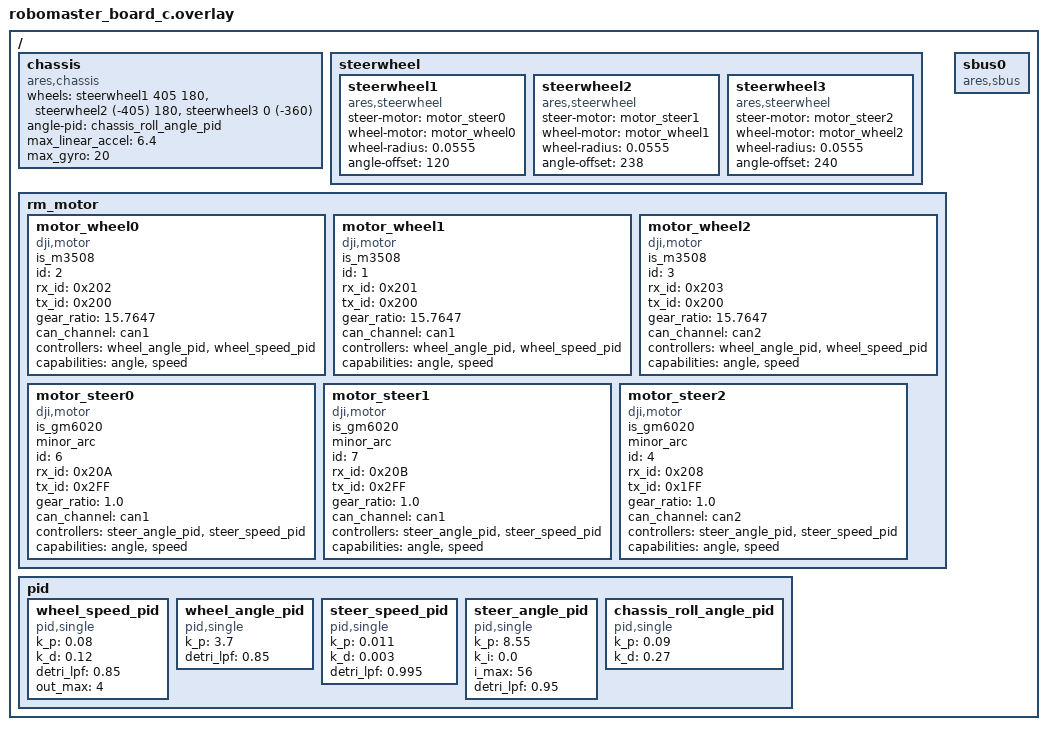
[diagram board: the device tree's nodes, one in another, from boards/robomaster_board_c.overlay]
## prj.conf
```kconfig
# 启用线程分析器
CONFIG_THREAD_ANALYZER=y
CONFIG_THREAD_ANALYZER_USE_LOG=y
CONFIG_THREAD_ANALYZER_USE_PRINTK=n
CONFIG_THREAD_NAME=y
# CONFIG_THREAD_ANALYZER_AUTO=y
# CONFIG_THREAD_ANALYZER_AUTO_INTERVAL=5
CONFIG_THREAD_ANALYZER_LOG_LEVEL_INF=y
CONFIG_THREAD_ANALYZER_AUTO_SEPARATE_CORES=n

# 启用 Shell 支持
CONFIG_SHELL=n
CONFIG_SHELL_BACKENDS=n
CONFIG_SHELL_BACKEND_SERIAL=n

# 启用 UART 控制台
CONFIG_UART_CONSOLE=y

# 禁用 SEGGER RTT
CONFIG_USE_SEGGER_RTT=n

# 启用事件支持
CONFIG_EVENTS=y

# 启用控制台支持
CONFIG_CONSOLE=y

# 启用日志系统
CONFIG_LOG=y
CONFIG_LOG_MODE_IMMEDIATE=y
CONFIG_LOG_PRINTK=y
CONFIG_LOG_BACKEND_UART=y
# CONFIG_LOG_MODE_IMMEDIATE=y

# 启用串行支持
CONFIG_SERIAL=y

# 禁用优化
CONFIG_NO_OPTIMIZATIONS=n

# 启用驱动
CONFIG_MOTOR=y
CONFIG_MOTOR_DJI=y
CONFIG_MOTOR_LOG_LEVEL=4
CONFIG_CAN=y
CONFIG_MOTOR_INIT_PRIORITY=90

CONFIG_ARES=y
CONFIG_ARES_SBUS=y
CONFIG_EKF_LIB=y
CONFIG_VOFA_LIB=y

CONFIG_AUTO_PROBE_GYRO_BIAS=y

# use ASYNC uart API
CONFIG_SERIAL=y
CONFIG_UART_ASYNC_API=y
CONFIG_UART_INTERRUPT_DRIVEN=y

CONFIG_DMA=y
CONFIG_DMA_STM32=y  # STM32 DMA 驱动
CONFIG_UART_STM32=y # STM32 UART 驱动
# CONFIG_STM32_UART_DMA=y

# CONFIG_HAS_STM32CUBE=y
# CONFIG_USE_STM32_HAL_DMA=y
CONFIG_SPI=y
CONFIG_SPI_STM32=y

CONFIG_CMSIS_DSP=y
CONFIG_CMSIS_DSP_MATRIX=y
CONFIG_CMSIS_DSP_CONTROLLER=y
CONFIG_CMSIS_DSP_FASTMATH=y

CONFIG_ZBUS=y
CONFIG_ZBUS_LOG_LEVEL_OFF=y
CONFIG_ZBUS_MSG_SUBSCRIBER=y
CONFIG_ZBUS_RUNTIME_OBSERVERS=y

CONFIG_CHASSIS=y
```

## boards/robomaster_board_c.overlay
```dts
/ {
    chassis: chassis {
        compatible = "ares,chassis";
        status = "okay";
        wheels = <&steerwheel1   405    180>,  /* 右前 */
                 <&steerwheel2 (-405)     180>,  /* 左前 */
                 <&steerwheel3     0  (-360)>;  /* 中后 */
        angle-pid = <&chassis_roll_angle_pid>;
        max_linear_accel = "6.4";
        max_gyro = "20";
    };

    steerwheel {
        steerwheel1: steerwheel1 {
            #wheel-cells = <2>;
            compatible = "ares,steerwheel";
            status = "okay";
            steer-motor = <&motor_steer0>;
            wheel-motor = <&motor_wheel0>;
            wheel-radius = "0.0555";
            angle-offset = "120";
        };

        steerwheel2: steerwheel2 {
            #wheel-cells = <2>;
            compatible = "ares,steerwheel";
            status = "okay";
            steer-motor = <&motor_steer1>;
            wheel-motor = <&motor_wheel1>;
            wheel-radius = "0.0555";
            angle-offset = "238";
        };

        steerwheel3: steerwheel3 {
            #wheel-cells = <2>;
            compatible = "ares,steerwheel";
            status = "okay";
            steer-motor = <&motor_steer2>;
            wheel-motor = <&motor_wheel2>;
            wheel-radius = "0.0555";
            angle-offset = "240";
        };
    };

    rm_motor {
        motor_wheel0: motor_wheel0 {
            compatible = "dji,motor";
            is_m3508;
            id = <2>;
            rx_id = <0x202>;
            tx_id = <0x200>;
            gear_ratio = "15.7647";
            status = "okay";
            can_channel = <&can1>;
            controllers = <&wheel_angle_pid &wheel_speed_pid>;
            capabilities = "angle", "speed";
        };

        motor_wheel1: motor_wheel1 {
            compatible = "dji,motor";
            is_m3508;
            id = <1>;
            rx_id = <0x201>;
            tx_id = <0x200>;
            gear_ratio = "15.7647";
            status = "okay";
            can_channel = <&can1>;
            controllers = <&wheel_angle_pid &wheel_speed_pid>;
            capabilities = "angle", "speed";
        };

        motor_wheel2: motor_wheel2 {
            compatible = "dji,motor";
            is_m3508;
            id = <3>;
            rx_id = <0x203>;
            tx_id = <0x200>;
            gear_ratio = "15.7647";
            status = "okay";
            can_channel = <&can2>;
            controllers = <&wheel_angle_pid &wheel_speed_pid>;
            capabilities = "angle", "speed";
        };

        motor_steer0: motor_steer0 {
            compatible = "dji,motor";
            is_gm6020;
            minor_arc;
            id = <6>;
            rx_id = <0x20A>;
            tx_id = <0x2FF>;
            gear_ratio = "1.0";
            status = "okay";
            can_channel = <&can1>;
            controllers = <&steer_angle_pid &steer_speed_pid>;
            capabilities = "angle", "speed";
        };

        motor_steer1: motor_steer1 {
            compatible = "dji,motor";
            is_gm6020;
            minor_arc;
            id = <7>;
            rx_id = <0x20B>;
            tx_id = <0x2FF>;
            gear_ratio = "1.0";
            status = "okay";
            can_channel = <&can1>;
            controllers = <&steer_angle_pid &steer_speed_pid>;
            capabilities = "angle", "speed";
        };

        motor_steer2: motor_steer2 {
            compatible = "dji,motor";
            is_gm6020;
            minor_arc;
            id = <4>;
            rx_id = <0x208>;
            tx_id = <0x1FF>;
            gear_ratio = "1.0";
            status = "okay";
            can_channel = <&can2>;
            controllers = <&steer_angle_pid &steer_speed_pid>;
            capabilities = "angle", "speed";
        };
    };

    pid {
        wheel_speed_pid: wheel_speed_pid {
            #controller-cells = <0>;
            compatible = "pid,single";
            k_p = "0.08";
            k_d = "0.12";
            detri_lpf = "0.85";
            out_max = "4";
        };

        wheel_angle_pid: wheel_angle_pid {
            #controller-cells = <0>;
            compatible = "pid,single";
            k_p = "3.7";
            detri_lpf = "0.85";
        };

        steer_speed_pid: steer_speed_pid {
            #controller-cells = <0>;
            compatible = "pid,single";
            k_p = "0.011";
            k_d = "0.003";
            detri_lpf = "0.995";
        };

        steer_angle_pid: steer_angle_pid {
            #controller-cells = <0>;
            compatible = "pid,single";
            k_p = "8.55";
            k_i = "0.0";
            i_max = "56";
            detri_lpf = "0.95";
        };

        chassis_roll_angle_pid: chassis_roll_angle_pid {
            #controller-cells = <0>;
            compatible = "pid,single";
            k_p = "0.09";
            k_d = "0.27";
        };
    };

    sbus0: sbus0 {
        compatible = "ares,sbus";
        status = "okay";
    };
};
```

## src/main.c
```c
/*
 * Copyright (c) 2024 ttwards <12411711@mail.sustech.edu.cn>
 *
 * SPDX-License-Identifier: Apache-2.0
 */

#include <math.h>
#include <stddef.h>
#include <stdint.h>
#include <string.h>
#include <zephyr/device.h>
#include <zephyr/logging/log.h>
#include <zephyr/kernel.h>
#include <zephyr/drivers/motor.h>
#include <zephyr/drivers/sbus.h>
#include <zephyr/drivers/chassis.h>
#include <ares/board/init.h>
#include "devices.h"

LOG_MODULE_REGISTER(main, LOG_LEVEL_DBG);

#define STICK_DEADZONE 0.06f
#define GEAR_SWITCH_DOWN_THRESHOLD -0.5f
#define GEAR_SWITCH_RELEASE_THRESHOLD -0.2f
#define HIGH_LINEAR_SPEED_SCALE 1.5f
#define HIGH_GYRO_SPEED_SCALE 15.0f
#define LOW_LINEAR_SPEED_SCALE 0.5f
#define LOW_GYRO_SPEED_SCALE 7.5f
#define BRAKE_LINEAR_DECEL_MPS2 5.0f
#define BRAKE_GYRO_DECEL_RADPS2 50.0f
#define DEFAULT_CONTROL_DT_SEC 0.005f
#define MAX_CONTROL_DT_SEC 0.05f
#define STOP_LINEAR_EPS 0.02f
#define STOP_GYRO_EPS 0.05f

static float control_dt_seconds(int64_t now_ms, int64_t *last_ms)
{
    if (*last_ms == 0) {
        *last_ms = now_ms;
        return DEFAULT_CONTROL_DT_SEC;
    }

    int64_t elapsed_ms = now_ms - *last_ms;
    *last_ms = now_ms;

    if (elapsed_ms <= 0) {
        return DEFAULT_CONTROL_DT_SEC;
    }

    float dt = (float)elapsed_ms / 1000.0f;

    if (dt > MAX_CONTROL_DT_SEC) {
        return MAX_CONTROL_DT_SEC;
    }

    return dt;
}

static float slew_toward(float current, float target, float max_delta)
{
    float delta = target - current;

    if (delta > max_delta) {
        return current + max_delta;
    }

    if (delta < -max_delta) {
        return current - max_delta;
    }

    return target;
}

static bool chassis_command_stopped(float speed_x, float speed_y, float gyro)
{
    return fabsf(speed_x) < STOP_LINEAR_EPS && fabsf(speed_y) < STOP_LINEAR_EPS &&
           fabsf(gyro) < STOP_GYRO_EPS;
}

static void enable_chassis_motors(void)
{
    motor_control(steer_motor1, ENABLE_MOTOR);
    motor_control(steer_motor2, ENABLE_MOTOR);
    motor_control(steer_motor3, ENABLE_MOTOR);
    motor_control(wheel_motor1, ENABLE_MOTOR);
    motor_control(wheel_motor2, ENABLE_MOTOR);
    motor_control(wheel_motor3, ENABLE_MOTOR);
}

void console_feedback(void *arg1, void *arg2, void *arg3)
{
    bool low_gear = true;
    bool gear_switch_armed = true;
    int64_t last_control_ms = 0;
    float cmd_speed_x = 0.0f;
    float cmd_speed_y = 0.0f;
    float cmd_gyro = 0.0f;

    while (1) {
        k_msleep(5);

        int64_t now_ms = k_uptime_get();
        float dt_sec = control_dt_seconds(now_ms, &last_control_ms);
        float angvel = -sbus_get_percent(sbus, 0);
        float X = sbus_get_percent(sbus, 3);
        float Y = sbus_get_percent(sbus, 1);
        float gear_switch = sbus_get_percent(sbus, 2);
        bool gear_switch_active = gear_switch < GEAR_SWITCH_RELEASE_THRESHOLD;

        if (gear_switch < GEAR_SWITCH_DOWN_THRESHOLD) {
            if (gear_switch_armed) {
                low_gear = !low_gear;
                gear_switch_armed = false;
            }
        } else if (gear_switch > GEAR_SWITCH_RELEASE_THRESHOLD) {
            gear_switch_armed = true;
        }

        float linear_speed_scale = low_gear ? LOW_LINEAR_SPEED_SCALE : HIGH_LINEAR_SPEED_SCALE;
        float gyro_speed_scale = low_gear ? LOW_GYRO_SPEED_SCALE : HIGH_GYRO_SPEED_SCALE;

        float linear_magnitude = sqrtf(X * X + Y * Y);

        if (linear_magnitude < STICK_DEADZONE) {
            X = 0;
            Y = 0;
        }

        if (gear_switch_active || fabsf(angvel) < STICK_DEADZONE) {
            angvel = 0;
        }

        bool in_deadzone = ((X == 0) && (Y == 0) && (angvel == 0));

        if (in_deadzone) {
            cmd_speed_x = slew_toward(cmd_speed_x, 0.0f, BRAKE_LINEAR_DECEL_MPS2 * dt_sec);
            cmd_speed_y = slew_toward(cmd_speed_y, 0.0f, BRAKE_LINEAR_DECEL_MPS2 * dt_sec);
            cmd_gyro = slew_toward(cmd_gyro, 0.0f, BRAKE_GYRO_DECEL_RADPS2 * dt_sec);

            if (chassis_command_stopped(cmd_speed_x, cmd_speed_y, cmd_gyro)) {
                cmd_speed_x = 0.0f;
                cmd_speed_y = 0.0f;
                cmd_gyro = 0.0f;
                chassis_set_static(chassis, true);
                chassis_set_speed(chassis, 0.0f, 0.0f);
                chassis_set_gyro(chassis, 0.0f);
            } else {
                chassis_set_static(chassis, false);
                chassis_set_speed(chassis, cmd_speed_x, cmd_speed_y);
                chassis_set_gyro(chassis, cmd_gyro);
            }
        } else {
            cmd_speed_x = -X * linear_speed_scale;
            cmd_speed_y = -Y * linear_speed_scale;
            cmd_gyro = angvel * gyro_speed_scale;

            chassis_set_static(chassis, false);
            chassis_set_speed(chassis, cmd_speed_x, cmd_speed_y);
            chassis_set_gyro(chassis, cmd_gyro);
        }
    }
}

K_THREAD_DEFINE(feedback_thread, 4096, console_feedback, NULL, NULL, NULL, 2, 0, 100);

int main(void)
{
    k_sleep(K_MSEC(2000));
    chassis_set_enabled(chassis, false);
    k_sleep(K_MSEC(100));
    enable_chassis_motors();
    chassis_set_enabled(chassis, true);
    chassis_set_gyro(chassis, 0);

    while (1) {
        k_sleep(K_MSEC(500));
    }

    return 0;
}
```

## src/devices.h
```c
#include <zephyr/device.h>
#include <zephyr/drivers/gpio.h>

/* Devicetree */
// #define UART_NODE DT_ALIAS(vofa)
// const struct device *uart_dev = DEVICE_DT_GET(UART_NODE);

// #define ACCEL_NODE DT_NODELABEL(bmi08x_accel)
// const struct device *accel_dev = DEVICE_DT_GET(ACCEL_NODE);

// #define GYRO_NODE DT_NODELABEL(bmi08x_gyro)
// const struct device *gyro_dev = DEVICE_DT_GET(GYRO_NODE);

#define WHEELMOTOR1_NODE DT_NODELABEL(motor_wheel0)
#define WHEELMOTOR2_NODE DT_NODELABEL(motor_wheel1)
#define WHEELMOTOR3_NODE DT_NODELABEL(motor_wheel2)

#define STEERMOTOR1_NODE DT_NODELABEL(motor_steer0)
#define STEERMOTOR2_NODE DT_NODELABEL(motor_steer1)
#define STEERMOTOR3_NODE DT_NODELABEL(motor_steer2)

#define CHASSIS_NODE DT_NODELABEL(chassis)

const struct device *wheel_motor1 = DEVICE_DT_GET(WHEELMOTOR1_NODE);
const struct device *wheel_motor2 = DEVICE_DT_GET(WHEELMOTOR2_NODE);
const struct device *wheel_motor3 = DEVICE_DT_GET(WHEELMOTOR3_NODE);

const struct device *steer_motor1 = DEVICE_DT_GET(STEERMOTOR1_NODE);
const struct device *steer_motor2 = DEVICE_DT_GET(STEERMOTOR2_NODE);
const struct device *steer_motor3 = DEVICE_DT_GET(STEERMOTOR3_NODE);

const struct device *chassis = DEVICE_DT_GET(CHASSIS_NODE);

#define SBUS_NODE DT_NODELABEL(sbus0)
const struct device *sbus = DEVICE_DT_GET(SBUS_NODE);
```
